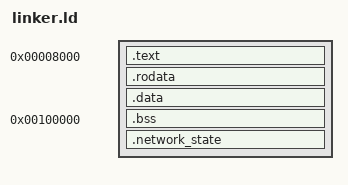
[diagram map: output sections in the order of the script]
ENTRY(_start)

SECTIONS
{
    . = 0x00008000;

    .text ALIGN(4096) :
    {
        *(.text*)
    }

    .rodata ALIGN(4096) :
    {
        *(.rodata*)
    }

    .data ALIGN(4096) :
    {
        *(.data*)
    }

    . = 0x00100000;

    .bss ALIGN(4096) :
    {
        __bss_start = .;
        *(COMMON)
        *(.bss*)
        __bss_end = .;
    }

    .network_state (NOLOAD) :
    {
        *(.network_state)
    }

    . = ALIGN(4096);
    __kernel_end = .;

    /DISCARD/ :
    {
        *(.comment)
        *(.note*)
        *(.eh_frame*)
    }
}
